# GD32H71x_72x register map
File version: 1.0
CPU: CM7 r1p2, little endian, MPU, FPU, 4 interrupt priority bits
Registers are 32-bit, read-write, reset 0x0 unless marked. A register's access mark holds for its fields unless they carry their own. Offsets are from the block's base; [hi:lo] are bit positions; {n}, {i} and the like mark numbered series; 'fields as' and 'values as' point back to an identical list.

## TRIGSEL — Trigger selection controller
Base 0x40017400
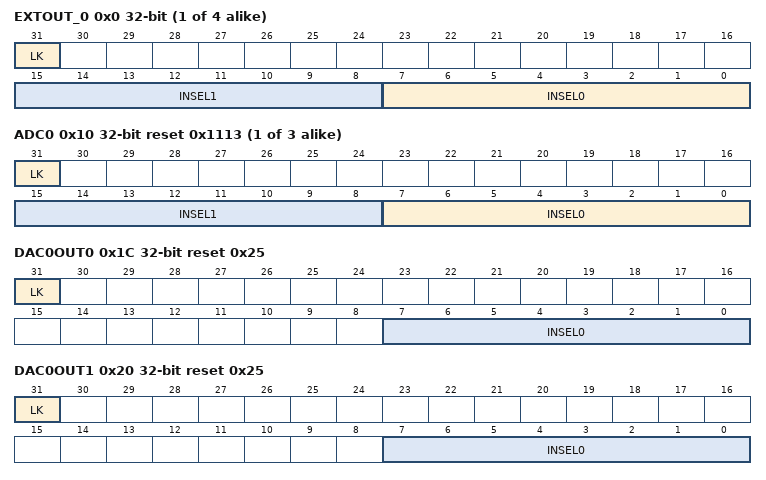
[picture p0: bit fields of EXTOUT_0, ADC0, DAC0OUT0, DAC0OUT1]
{0x0+4i} EXTOUT_{i} (i=0..3) — Trigger selection for EXTOUT register {i}
  [31] LK — TRIGSEL register lock.
  [15:8] INSEL1 — Trigger input source selection for output1
  [7:0] INSEL0 — Trigger input source selection for output0
{0x10+4i} ADC{i} reset 0x1113 (i=0..2) — Trigger selection for ADC{i} register
  fields as EXTOUT_0
0x1C DAC0OUT0 reset 0x25 — Trigger selection for DAC0_OUT0 register
  [31] LK — TRIGSEL register lock.
  [7:0] INSEL0 — Trigger input source selection for output0
0x20 DAC0OUT1 reset 0x25 — Trigger selection for DAC0_OUT1 register
  fields as DAC0OUT0
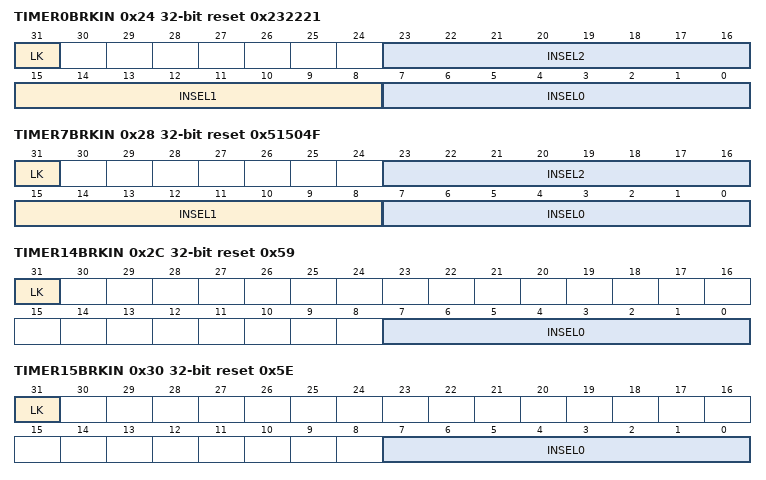
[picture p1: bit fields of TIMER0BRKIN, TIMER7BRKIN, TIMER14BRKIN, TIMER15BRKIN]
0x24 TIMER0BRKIN reset 0x232221 — Trigger selection for TIMER0_BRKIN register
  [31] LK — TRIGSEL register lock.
  [23:16] INSEL2 — Trigger input source selection for output2
  [15:8] INSEL1 — Trigger input source selection for output1
  [7:0] INSEL0 — Trigger input source selection for output0
0x28 TIMER7BRKIN reset 0x51504F — Trigger selection for TIMER7_BRKIN register
  fields as TIMER0BRKIN
0x2C TIMER14BRKIN reset 0x59 — Trigger selection for TIMER14_BRKIN register
  fields as DAC0OUT0
0x30 TIMER15BRKIN reset 0x5E — Trigger selection for TIMER15_BRKIN register
  fields as DAC0OUT0
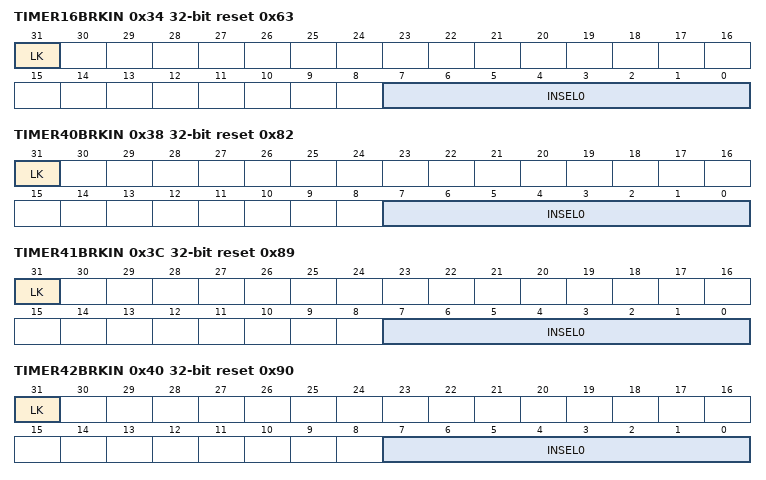
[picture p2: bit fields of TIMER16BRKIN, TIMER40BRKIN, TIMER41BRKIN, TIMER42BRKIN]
0x34 TIMER16BRKIN reset 0x63 — Trigger selection for TIMER16_BRKIN register
  fields as DAC0OUT0
0x38 TIMER40BRKIN reset 0x82 — Trigger selection for TIMER40_BRKIN register
  fields as DAC0OUT0
0x3C TIMER41BRKIN reset 0x89 — Trigger selection for TIMER41_BRKIN register
  fields as DAC0OUT0
0x40 TIMER42BRKIN reset 0x90 — Trigger selection for TIMER42_BRKIN register
  fields as DAC0OUT0
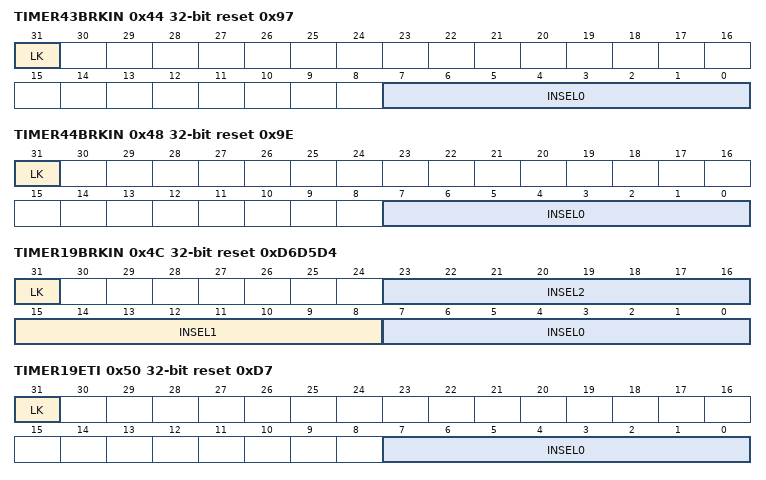
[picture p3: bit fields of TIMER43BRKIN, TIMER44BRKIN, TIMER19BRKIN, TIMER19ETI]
0x44 TIMER43BRKIN reset 0x97 — Trigger selection for TIMER43_BRKIN register
  fields as DAC0OUT0
0x48 TIMER44BRKIN reset 0x9E — Trigger selection for TIMER44_BRKIN register
  fields as DAC0OUT0
0x4C TIMER19BRKIN reset 0xD6D5D4 — Trigger selection for TIMER19_BRKIN register
  fields as TIMER0BRKIN
0x50 TIMER19ETI reset 0xD7 — Trigger selection for TIMER19_ETI register
  fields as DAC0OUT0
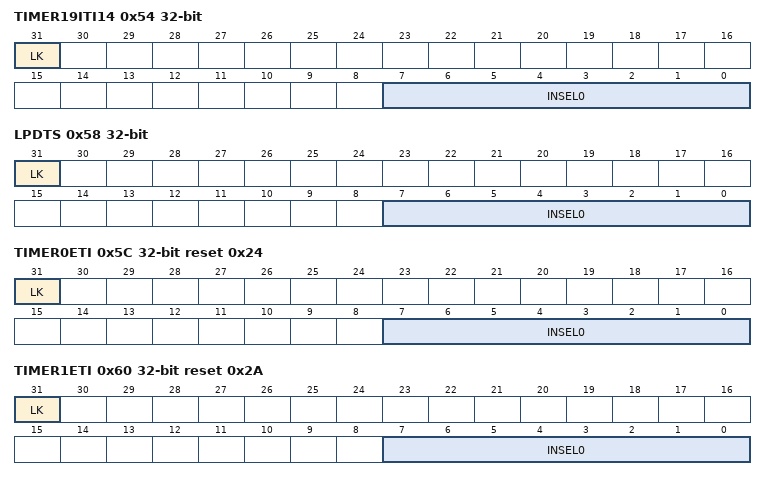
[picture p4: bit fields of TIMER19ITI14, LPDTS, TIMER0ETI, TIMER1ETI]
0x54 TIMER19ITI14 — Trigger selection for TIMER19_ITI14 register
  fields as DAC0OUT0
0x58 LPDTS — Trigger selection for LPDTS register
  fields as DAC0OUT0
0x5C TIMER0ETI reset 0x24 — Trigger selection for TIMER0_ETI register
  fields as DAC0OUT0
0x60 TIMER1ETI reset 0x2A — Trigger selection for TIMER1_ETI register
  fields as DAC0OUT0
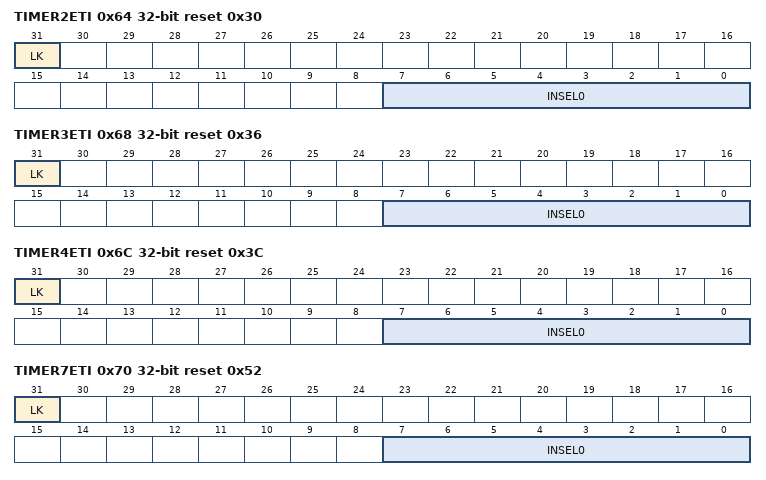
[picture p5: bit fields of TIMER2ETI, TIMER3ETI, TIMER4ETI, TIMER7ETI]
0x64 TIMER2ETI reset 0x30 — Trigger selection for TIMER2_ETI register
  fields as DAC0OUT0
0x68 TIMER3ETI reset 0x36 — Trigger selection for TIMER3_ETI register
  fields as DAC0OUT0
0x6C TIMER4ETI reset 0x3C — Trigger selection for TIMER4_ETI register
  fields as DAC0OUT0
0x70 TIMER7ETI reset 0x52 — Trigger selection for TIMER7_ETI register
  fields as DAC0OUT0
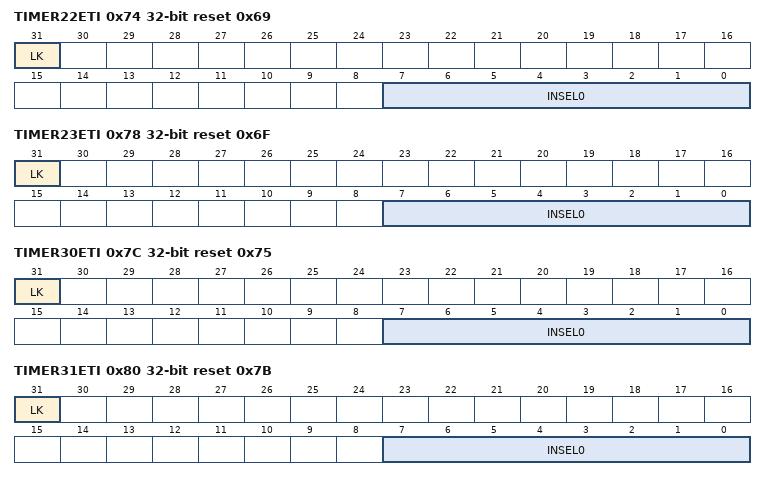
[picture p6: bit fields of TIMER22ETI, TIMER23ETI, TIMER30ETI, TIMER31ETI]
0x74 TIMER22ETI reset 0x69 — Trigger selection for TIMER22_ETI register
  fields as DAC0OUT0
0x78 TIMER23ETI reset 0x6F — Trigger selection for TIMER23_ETI register
  fields as DAC0OUT0
0x7C TIMER30ETI reset 0x75 — Trigger selection for TIMER30_ETI register
  fields as DAC0OUT0
0x80 TIMER31ETI reset 0x7B — Trigger selection for TIMER31_ETI register
  fields as DAC0OUT0
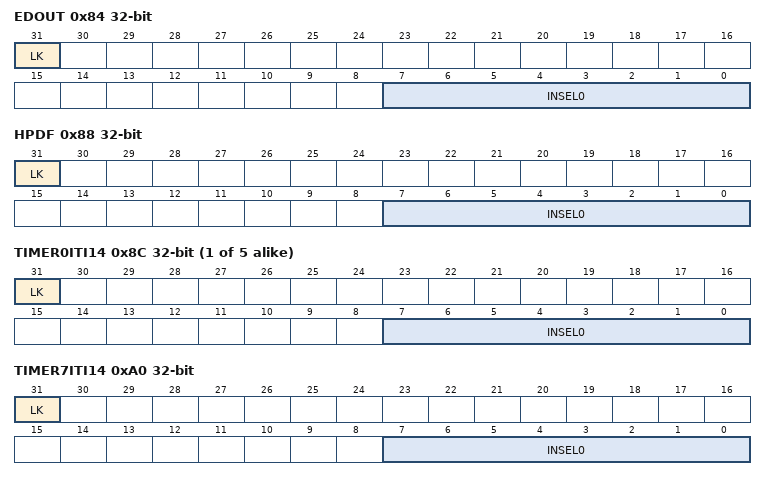
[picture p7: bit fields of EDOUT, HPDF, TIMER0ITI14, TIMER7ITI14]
0x84 EDOUT — Trigger selection for EDOUT register
  fields as DAC0OUT0
0x88 HPDF — Trigger selection for HPDF register
  fields as DAC0OUT0
{0x8C+4i} TIMER{i}ITI14 (i=0..4) — Trigger selection for TIMER{i}_ITI14 register
  fields as DAC0OUT0
0xA0 TIMER7ITI14 — Trigger selection for TIMER7_ITI14 register
  fields as DAC0OUT0
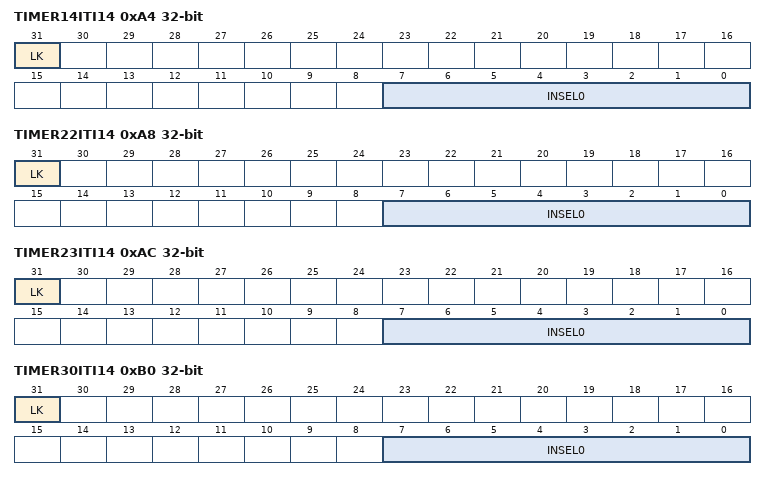
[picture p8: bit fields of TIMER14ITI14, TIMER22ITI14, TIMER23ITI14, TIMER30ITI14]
0xA4 TIMER14ITI14 — Trigger selection for TIMER14_ITI14 register
  fields as DAC0OUT0
0xA8 TIMER22ITI14 — Trigger selection for TIMER22_ITI14 register
  fields as DAC0OUT0
0xAC TIMER23ITI14 — Trigger selection for TIMER23_ITI14 register
  fields as DAC0OUT0
0xB0 TIMER30ITI14 — Trigger selection for TIMER30_ITI14 register
  fields as DAC0OUT0
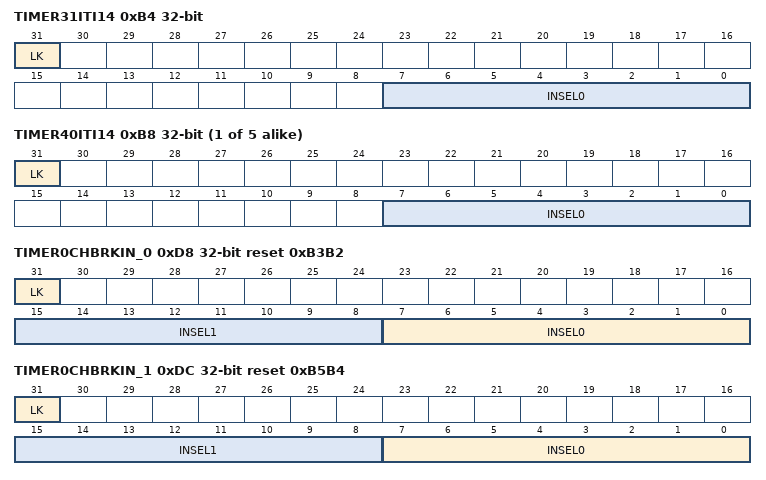
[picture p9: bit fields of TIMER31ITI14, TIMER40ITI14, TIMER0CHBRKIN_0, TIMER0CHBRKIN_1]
0xB4 TIMER31ITI14 — Trigger selection for TIMER31_ITI14 register
  fields as DAC0OUT0
{0x18+4i} TIMER{i}ITI14 (i=40..44) — Trigger selection for TIMER{i}_ITI14 register
  fields as DAC0OUT0
0xD8 TIMER0CHBRKIN_0 reset 0xB3B2 — Trigger selection for TIMER0_CHBRKIN register 0
  fields as EXTOUT_0
0xDC TIMER0CHBRKIN_1 reset 0xB5B4 — Trigger selection for TIMER0_CHBRKIN register 1
  fields as EXTOUT_0
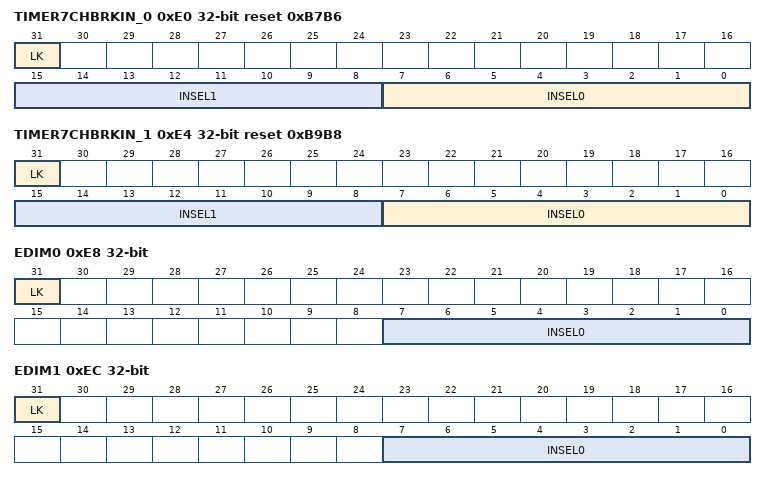
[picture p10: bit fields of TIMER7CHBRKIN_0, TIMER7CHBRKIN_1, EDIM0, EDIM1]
0xE0 TIMER7CHBRKIN_0 reset 0xB7B6 — Trigger selection for TIMER7_CHBRKIN register 0
  fields as EXTOUT_0
0xE4 TIMER7CHBRKIN_1 reset 0xB9B8 — Trigger selection for TIMER7_CHBRKIN register 1
  fields as EXTOUT_0
0xE8 EDIM0 — Trigger selection for EDIM0 register
  fields as DAC0OUT0
0xEC EDIM1 — Trigger selection for EDIM1 register
  fields as DAC0OUT0
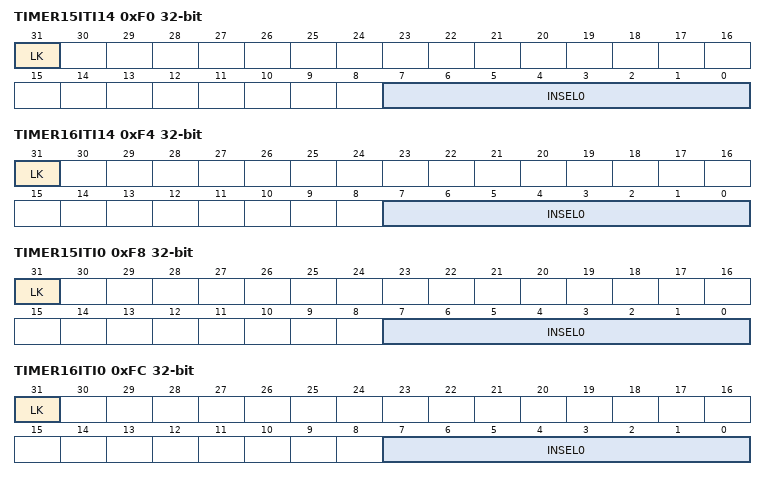
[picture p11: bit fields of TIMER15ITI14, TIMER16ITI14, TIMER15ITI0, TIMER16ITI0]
0xF0 TIMER15ITI14 — Trigger selection for TIMER15_ITI14 register
  fields as DAC0OUT0
0xF4 TIMER16ITI14 — Trigger selection for TIMER16_ITI14 register
  fields as DAC0OUT0
0xF8 TIMER15ITI0 — Trigger selection for TIMER15_ITI0 register
  fields as DAC0OUT0
0xFC TIMER16ITI0 — Trigger selection for TIMER16_ITI0 register
  fields as DAC0OUT0
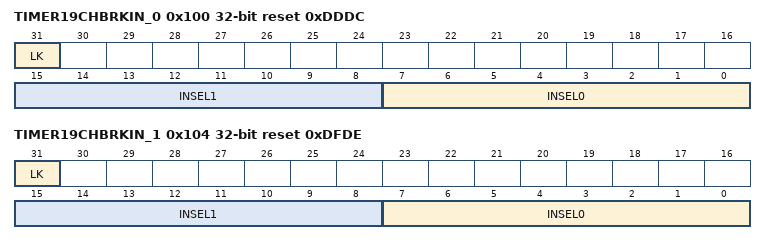
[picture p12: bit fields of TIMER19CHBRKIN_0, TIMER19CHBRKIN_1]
0x100 TIMER19CHBRKIN_0 reset 0xDDDC — Trigger selection for TIMER19_CHBRKIN register 0
  fields as EXTOUT_0
0x104 TIMER19CHBRKIN_1 reset 0xDFDE — Trigger selection for TIMER19_CHBRKIN register 1
  fields as EXTOUT_0
